AUTOSAR XML (schema 4-2-1)
package /ComponentTypes
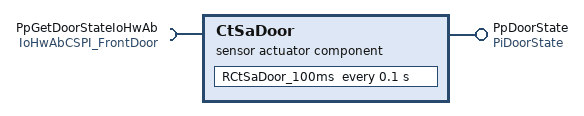
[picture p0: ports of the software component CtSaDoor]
  sensor actuator sw component type CtSaDoor
    provide port PpDoorState: nonqueued-sender-com-spec{data-element=DeDoorState, init-value=constant-reference=CDoorClosed}, provided-interface=PiDoorState
    require port PpGetDoorStateIoHwAb: required-interface=IoHwAbCSPI_FrontDoor
    behavior CtSaDoor_InternalBehavior: data-type-mapping=DemoTypeMappingCtSaDoor, supports-multiple-instantiation=true
      timing event TMT_Door: start-on-event=RCtSaDoor_100ms, period=0.1
      runnable RCtSaDoor_100ms
        data-send-points:
          access SEND_PpDoorState_DoorState: accessed-variable=PpDoorState.DeDoorState
        sync call SC_PpGetDoorStateIoHwAb_IoHwAb_Get_FrontStat: operation=PpGetDoorStateIoHwAb.IoHwAb_Get_FrontStat, timeout=0
  swc implementation CtSaDoor_Implementation: behavior=CtSaDoor_InternalBehavior
    code-descriptors:
      code Default: artifact-descriptors=autosar-engineering-object={short-label=Default, category=SWSRC}
